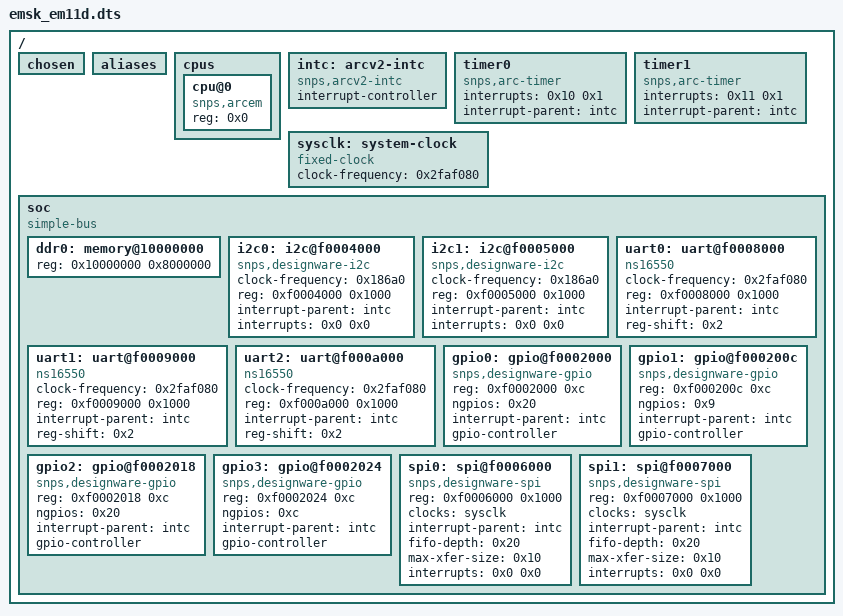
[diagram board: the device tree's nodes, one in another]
/dts-v1/;

/ {
	#address-cells = < 0x1 >;
	#size-cells = < 0x1 >;
	chosen {
	};
	aliases {
	};
	cpus {
		#address-cells = < 0x1 >;
		#size-cells = < 0x0 >;
		cpu@0 {
			device_type = "cpu";
			compatible = "snps,arcem";
			reg = < 0x0 >;
		};
	};
	intc: arcv2-intc {
		compatible = "snps,arcv2-intc";
		interrupt-controller;
		#interrupt-cells = < 0x2 >;
		phandle = < 0x1 >;
	};
	timer0: timer0 {
		compatible = "snps,arc-timer";
		interrupts = < 0x10 0x1 >;
		interrupt-parent = < &intc >;
	};
	timer1: timer1 {
		compatible = "snps,arc-timer";
		interrupts = < 0x11 0x1 >;
		interrupt-parent = < &intc >;
	};
	sysclk: system-clock {
		compatible = "fixed-clock";
		clock-frequency = < 0x2faf080 >;
		#clock-cells = < 0x0 >;
		phandle = < 0x2 >;
	};
	soc {
		#address-cells = < 0x1 >;
		#size-cells = < 0x1 >;
		compatible = "simple-bus";
		ranges;
		ddr0: memory@10000000 {
			device_type = "memory";
			reg = < 0x10000000 0x8000000 >;
		};
		i2c0: i2c@f0004000 {
			compatible = "snps,designware-i2c";
			clock-frequency = < 0x186a0 >;
			#address-cells = < 0x1 >;
			#size-cells = < 0x0 >;
			reg = < 0xf0004000 0x1000 >;
			interrupt-parent = < &intc >;
			interrupts = < 0x0 0x0 >;
		};
		i2c1: i2c@f0005000 {
			compatible = "snps,designware-i2c";
			clock-frequency = < 0x186a0 >;
			#address-cells = < 0x1 >;
			#size-cells = < 0x0 >;
			reg = < 0xf0005000 0x1000 >;
			interrupt-parent = < &intc >;
			interrupts = < 0x0 0x0 >;
		};
		uart0: uart@f0008000 {
			compatible = "ns16550";
			clock-frequency = < 0x2faf080 >;
			reg = < 0xf0008000 0x1000 >;
			interrupt-parent = < &intc >;
			reg-shift = < 0x2 >;
		};
		uart1: uart@f0009000 {
			compatible = "ns16550";
			clock-frequency = < 0x2faf080 >;
			reg = < 0xf0009000 0x1000 >;
			interrupt-parent = < &intc >;
			reg-shift = < 0x2 >;
		};
		uart2: uart@f000a000 {
			compatible = "ns16550";
			clock-frequency = < 0x2faf080 >;
			reg = < 0xf000a000 0x1000 >;
			interrupt-parent = < &intc >;
			reg-shift = < 0x2 >;
		};
		gpio0: gpio@f0002000 {
			compatible = "snps,designware-gpio";
			reg = < 0xf0002000 0xc >;
			ngpios = < 0x20 >;
			interrupt-parent = < &intc >;
			gpio-controller;
			#gpio-cells = < 0x2 >;
		};
		gpio1: gpio@f000200c {
			compatible = "snps,designware-gpio";
			reg = < 0xf000200c 0xc >;
			ngpios = < 0x9 >;
			interrupt-parent = < &intc >;
			gpio-controller;
			#gpio-cells = < 0x2 >;
		};
		gpio2: gpio@f0002018 {
			compatible = "snps,designware-gpio";
			reg = < 0xf0002018 0xc >;
			ngpios = < 0x20 >;
			interrupt-parent = < &intc >;
			gpio-controller;
			#gpio-cells = < 0x2 >;
		};
		gpio3: gpio@f0002024 {
			compatible = "snps,designware-gpio";
			reg = < 0xf0002024 0xc >;
			ngpios = < 0xc >;
			interrupt-parent = < &intc >;
			gpio-controller;
			#gpio-cells = < 0x2 >;
		};
		spi0: spi@f0006000 {
			compatible = "snps,designware-spi";
			reg = < 0xf0006000 0x1000 >;
			clocks = < &sysclk >;
			interrupt-parent = < &intc >;
			fifo-depth = < 0x20 >;
			max-xfer-size = < 0x10 >;
			#address-cells = < 0x1 >;
			#size-cells = < 0x0 >;
			interrupts = < 0x0 0x0 >;
		};
		spi1: spi@f0007000 {
			compatible = "snps,designware-spi";
			reg = < 0xf0007000 0x1000 >;
			clocks = < &sysclk >;
			interrupt-parent = < &intc >;
			fifo-depth = < 0x20 >;
			max-xfer-size = < 0x10 >;
			#address-cells = < 0x1 >;
			#size-cells = < 0x0 >;
			interrupts = < 0x0 0x0 >;
		};
	};
};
